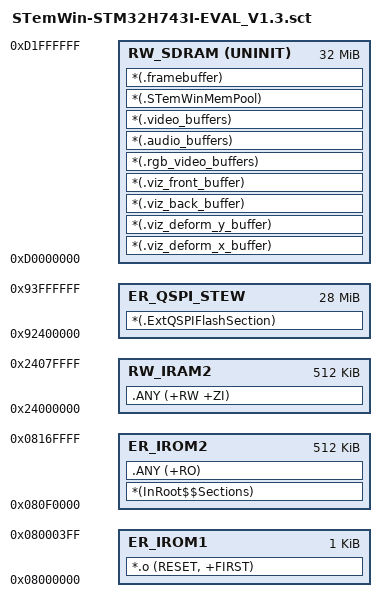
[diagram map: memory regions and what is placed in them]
; *************************************************************
; *** Scatter-Loading Description File generated by uVision ***
; *************************************************************

LR_IROM1 0x08000000 0x400  {    ; load region size_region
	ER_IROM1 0x08000000 0x400 {  ; load address = execution address
		*.o (RESET, +FIRST)
	}
}

LR_IROM2 0x080F0000 0x80000 {    ; load region size_region
	ER_IROM2 0x080F0000 0x80000 {
		*(InRoot$$Sections)
		.ANY (+RO)
	}
	RW_IRAM2 0x24000000 0x80000 {
		.ANY (+RW +ZI)
			
	}
	RW_SDRAM 0xD0000000 UNINIT 0x2000000 {
	    *(.viz_deform_x_buffer)
		*(.viz_deform_y_buffer)
		*(.viz_back_buffer)
		*(.viz_front_buffer)
		*(.rgb_video_buffers)
		*(.audio_buffers)
		*(.video_buffers)
		*(.STemWinMemPool)
		*(.framebuffer)

	} 
}

LR_QSPI_STEW 0x92400000 0x1C00000 {
	ER_QSPI_STEW  0x92400000 0x1C00000 {
		*(.ExtQSPIFlashSection)
	}
}

